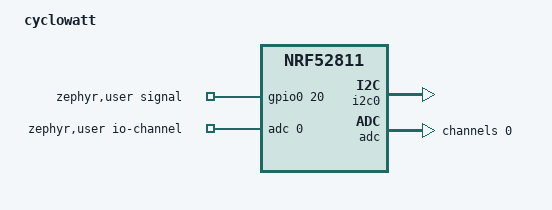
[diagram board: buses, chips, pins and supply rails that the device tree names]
/dts-v1/;
#include <nordic/nrf52811_qfaa.dtsi>
#include "cyclowatt-pinctrl.dtsi"

/ {
	
	model = "cyclowatt";
	compatible = "eth,cyclowatt";

	chosen {
		zephyr,sram = &sram0;
		zephyr,flash = &flash0;
		zephyr,code-partition = &slot0_partition;
	};

	zephyr,user {
		signal-gpios = <&gpio0 20 GPIO_ACTIVE_HIGH>;
		io-channels = <&adc 0>;
	};
};



&i2c0 {
  status = "okay";
  pinctrl-0 = <&i2c1_sleep>;
	pinctrl-1 = <&i2c1_sleep>;
	pinctrl-names = "default", "sleep";
};

&gpio0 {
	status = "okay";
	label = "GPIO0";
};

&gpiote {
	status = "okay";
};

&flash0 {
	partitions {
		compatible = "fixed-partitions";
		#address-cells = <1>;
		#size-cells = <1>;

		boot_partition: partition@0 {
			label = "mcuboot";
			reg = <0x00000000 DT_SIZE_K(48)>;
		};

		slot0_partition: partition@c000 {
			label = "image-0";
			reg = <0x0000c000 DT_SIZE_K(56)>;
		};

		slot1_partition: partition@1a000 {
			label = "image-1";
			reg = <0x0001a000 DT_SIZE_K(56)>;
		};

		storage_partition: partition@28000 {
			label = "storage";
			reg = <0x00028000 DT_SIZE_K(32)>;
		};

	};
};

	// used for acquiring the reading of the load cell
&adc {
	status = "okay";
	#address-cells = <1>;
	#size-cells = <0>;
	thermistor0: channel@0 {
		reg = <0>;
		zephyr,gain = "ADC_GAIN_1_6";
		zephyr,reference = "ADC_REF_INTERNAL";
		zephyr,acquisition-time = <ADC_ACQ_TIME(ADC_ACQ_TIME_MICROSECONDS, 5)>;
		zephyr,input-positive = <NRF_SAADC_AIN2>;
		zephyr,resolution = <12>;
		zephyr,oversampling = <4>;
	};

};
